# NUC400_v1 register map
File version: 1.0
Registers are 32-bit, read-write, reset 0x0 unless marked. A register's access mark holds for its fields unless they carry their own. Offsets are from the block's base; [hi:lo] are bit positions; {n}, {i} and the like mark numbered series; 'fields as' and 'values as' point back to an identical list.

## CLK — CLK Register Map
Base 0x40000200
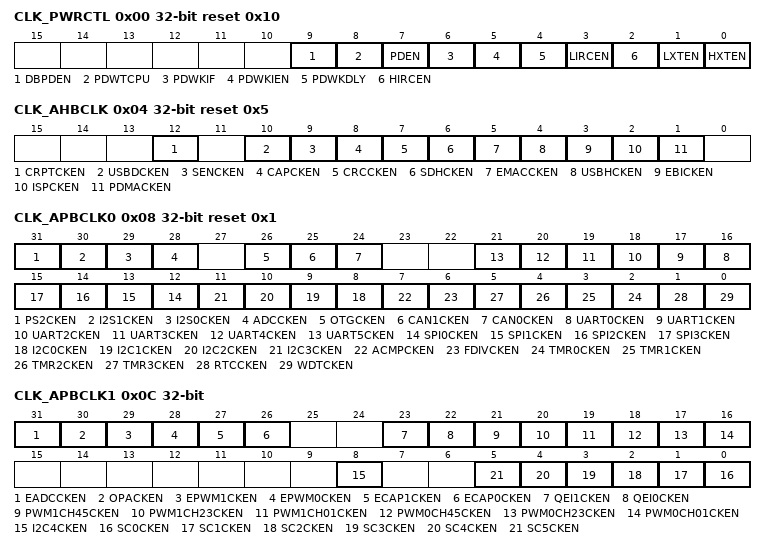
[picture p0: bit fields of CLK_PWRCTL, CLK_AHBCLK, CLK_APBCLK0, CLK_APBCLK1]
0x00 CLK_PWRCTL reset 0x10 (reset mask 0xFFFFFFF0) — System Power-down Control Register
  [9] DBPDEN — Chip Entering Power-Down Even ICE Connected
    0=Chip enters power-down disabled in Debug mode; 1=Chip enters power-down enabled in Debug mode
  [8] PDWTCPU — This Bit Control The Power-Down Entry Condition (Write Protect)
    0=Chip enters Power-down mode when the PDEN bit is set to 1; 1=Chip enters Power-down mode when the both PDWTCPU and PDEN bits are set to 1 and CPU run WFI instruction
  [7] PDEN — System Power-Down Enable Bit (Write Protect). When this bit is set to 1, Power-down mode is enabled and chip power-down behavior will depend on the PDWTCPU bit. (a) If the PDWTCPU is 0, then the chip enters Power-down mode immediately after the PDEN bit set. ( default) (b) if the PDWTCPU is 1, then the chip keeps active till the CPU sleep mode is also active and then the chip enters Power-down mode. When chip wakes up from Power-down mode, this bit is auto cleared. Users need to set this bit again for next power-down. In Power-down mode, HXT and the HIRC will be disabled in this mode, but the LXT and LIRC are not controlled by Power-down mode. In Power-down mode, the PLL and system clock are disabled, and ignored the clock source selection. The clocks of peripheral are not controlled by Power-down mode, if the peripheral clock source is from LXT or the LIRC.
    0=Chip operating normally or chip in idle mode by WFI command; 1=Chip enters Power-down mode instant or waits CPU sleep command WFI
  [6] PDWKIF — Power-Down Mode Wake-Up Interrupt Status. Set by "power-down wake-up event", it indicates that resume from Power-down mode" The flag is set if the GPIO, USB, UART, WDT, CAN, ACMP, BOD, RTC or SDHOST wake-up occurred. Note1: Write 1 to clear the bit to 0. Note2: This bit works only if PDWKIEN (CLK_PWRCTL[5]) set to 1.
  [5] PDWKIEN — Power-Down Mode Wake-Up Interrupt Enable Bit (Write Protect). Note: The interrupt will occur when both PDWKIF and PDWKIEN are high.
    0=Power-down Mode Wake-up Interrupt Disabled; 1=Power-down Mode Wake-up Interrupt Enabled
  [4] PDWKDLY — Wake-Up Delay Counter Enable Bit (Write Protect). When the chip wakes up from Power-down mode, the clock control will delay certain clock cycles to wait system clock stable. The delayed clock cycle is 4096 clock cycles when chip work at HXT, and 256 clock cycles when chip works at HIRC.
    0=Clock cycles delay Disabled; 1=Clock cycles delay Enabled
  [3] LIRCEN — 10 KHz Internal Low-Speed Oscillator (LIRC) Enable Bit (Write Protect)
    0=LIRC Disabled; 1=LIRC Enabled (default 1)
  [2] HIRCEN — 22.1184 MHz Internal High-Speed Oscillator Clock (HIRC) Enable Bit (Write Protect)
    0=HIRC Disabled; 1=HIRC Enabled
  [1] LXTEN — 32.768 KHz External Low-Speed Crystal Clock (LXT) Enable Bit (Write Protect)
    0=LXT Disabled; 1=LXT (Normal operation) Enabled
  [0] HXTEN — 4~24 MHz External High-Speed Crystal Clock (HXT) Enable Bit (Write Protect). The bit default value is set by flash controller user configuration register config0 [26:24]. When the default clock source is from 4~24 MHz external high-speed crystal, this bit is set to 1 automatically
    0=HXT Disabled; 1=HXT Enabled
0x04 CLK_AHBCLK reset 0x5 — AHB Devices Clock Enable Control Register
  [12] CRPTCKEN — Cryptographic Accelerator Clock Enable Bit
    0=Cryptographic Accelerator clock Disabled; 1=Cryptographic Accelerator clock Enabled
  [10] USBDCKEN — USB 2.0 Device Clock Enable Bit
    0=USB device controller's clock Disabled; 1=USB device controller's clock Enabled
  [9] SENCKEN — Sensor Clock Enable Bit
    0=Sensor clock Disabled; 1=Sensor clock Enabled
  [8] CAPCKEN — Image Capture Interface Controller Clock Enable Bit
    0=CAP controller's clock Disabled; 1=CAP controller's clock Enabled
  [7] CRCCKEN — CRC Generator Controller Clock Enable Bit
    0=CRC engine clock Disabled; 1=CRC engine clock Enabled
  [6] SDHCKEN — SDHOST Controller Clock Enable Bit
    0=SDHOST engine clock Disabled; 1=SDHOST engine clock Enabled
  [5] EMACCKEN — Ethernet Controller Clock Enable Bit (NUC472 Only)
    0=Ethernet Controller engine clock Disabled; 1=Ethernet Controller engine clock Enabled
  [4] USBHCKEN — USB HOST Controller Clock Enable Bit
    0=USB HOST engine clock Disabled; 1=USB HOST engine clock Enabled
  [3] EBICKEN — EBI Controller Clock Enable Bit
    0=EBI engine clock Disabled; 1=EBI engine clock Enabled
  [2] ISPCKEN — Flash ISP Controller Clock Enable Bit
    0=Flash ISP engine clock Disabled; 1=Flash ISP engine clock Enabled
  [1] PDMACKEN — PDMA Controller Clock Enable Bit
    0=PDMA engine clock Disabled; 1=PDMA engine clock Enabled
0x08 CLK_APBCLK0 reset 0x1 — APB Devices Clock Enable Control Register 0
  [31] PS2CKEN — PS/2 Clock Enable Bit
    0=PS/2 clock Disabled; 1=PS/2 clock Enabled
  [30] I2S1CKEN — I2S1 Clock Enable Bit
    0=I2S1 Clock Disabled; 1=I2S1 Clock Enabled
  [29] I2S0CKEN — I2S0 Clock Enable Bit
    0=I2S Clock Disabled; 1=I2S Clock Enabled
  [28] ADCCKEN — Analog-Digital-Converter (ADC) Clock Enable Bit
    0=ADC clock Disabled; 1=ADC clock Enabled
  [26] OTGCKEN — USB 2.0 OTG Device Controller Clock Enable Bit
    0=OTG clock Disabled; 1=OTG clock Enabled
  [25] CAN1CKEN — CAN Bus Controller-1 Clock Enable Bit
    0=CAN1 clock Disabled; 1=CAN1 clock Enabled
  [24] CAN0CKEN — CAN Bus Controller-0 Clock Enable Bit
    0=CAN0 clock Disabled; 1=CAN0 clock Enabled
  [n+16] UART{n}CKEN (n=0..5) — UART{n} Clock Enable Bit
    0=UART{n} clock Disabled; 1=UART{n} clock Enabled
  [n+12] SPI{n}CKEN (n=0..3) — SPI{n} Clock Enable Bit
    0=SPI{n} Clock Disabled; 1=SPI{n} Clock Enabled
  [n+8] I2C{n}CKEN (n=0..3) — I2C{n} Clock Enable Bit
    0=I2C{n} Clock Disabled; 1=I2C{n} Clock Enabled
  [7] ACMPCKEN — Analog Comparator Clock Enable Bit
    0=Analog Comparator Clock Disabled; 1=Analog Comparator Clock Enabled
  [6] FDIVCKEN — Frequency Divider Output Clock Enable Bit
    0=FDIV Clock Disabled; 1=FDIV Clock Enabled
  [n+2] TMR{n}CKEN (n=0..3) — Timer{n} Clock Enable Bit
    0=Timer{n} Clock Disabled; 1=Timer{n} Clock Enabled
  [1] RTCCKEN — Real-Time-Clock APB Interface Clock Enable Bit. This bit is used to control the RTC APB clock only, The RTC engine clock source is from the 32.768 kHz external low-speed crystal.
    0=RTC Clock Disabled; 1=RTC Clock Enabled
  [0] WDTCKEN — Watchdog Timer Clock Enable Bit (Write Protect). This bit is the protected bit, which means programming this needs to write "59h", "16h", "88h" to address 0x4000_0100 to disable register protection. Refer to the register REGWRPROT at address GCR_BA+0x100.
    0=Watchdog Timer Clock Disabled; 1=Watchdog Timer Clock Enabled
0x0C CLK_APBCLK1 — APB Devices Clock Enable Control Register 1
  [31] EADCCKEN — Enhanced Analog-Digital-Converter (E ADC) Clock Enable Bit
    0=EADC clock Disabled; 1=EADC clock Enabled
  [30] OPACKEN — OP Amplifier (OPA) Clock Enable Bit
    0=OPA clock Disabled; 1=OPA clock Enabled
  [29] EPWM1CKEN — Enhanced PWM1 (EPWM) Clock Enable Bit
    0=EPWM1 clock Disabled; 1=EPWM1 clock Enabled
  [28] EPWM0CKEN — Enhanced PWM0 (EPWM) Clock Enable Bit
    0=EPWM0 clock Disabled; 1=EPWM0 clock Enabled
  [27] ECAP1CKEN — Enhanced CAP (ECAP1) Clock Enable Bit
    0=ECAP1 clock Disabled; 1=ECAP1 clock Enabled
  [26] ECAP0CKEN — Enhanced CAP (ECAP0) Clock Enable Bit
    0=ECAP0 clock Disabled; 1=ECAP0 clock Enabled
  [23] QEI1CKEN — Quadrature Encoder Interface (QEI1) Clock Enable Bit
    0=QEI1 clock Disabled; 1=QEI1 clock Enabled
  [22] QEI0CKEN — Quadrature Encoder Interface (QEI0) Clock Enable Bit
    0=QEI0 clock Disabled; 1=QEI0 clock Enabled
  [21] PWM1CH45CKEN — PWM1_45 Clock Enable Bit
    0=PWM1_45 Clock Disabled; 1=PWM1_45 Clock Enabled
  [20] PWM1CH23CKEN — PWM1_23 Clock Enable Bit
    0=PWM1_23 Clock Disabled; 1=PWM1_23 Clock Enabled
  [19] PWM1CH01CKEN — PWM1_01 Clock Enable Bit
    0=PWM1_01 Clock Disabled; 1=PWM1_01 Clock Enabled
  [18] PWM0CH45CKEN — PWM0_45 Clock Enable Bit
    0=PWM0_45 Clock Disabled; 1=PWM0_45 Clock Enabled
  [17] PWM0CH23CKEN — PWM0_23 Clock Enable Bit
    0=PWM0_23 Clock Disabled; 1=PWM0_23 Clock Enabled
  [16] PWM0CH01CKEN — PWM0_01 Clock Enable Bit
    0=PWM0_01 Clock Disabled; 1=PWM0_01 Clock Enabled
  [8] I2C4CKEN — I2C4 Clock Enable Bit
    0=I2C4 Clock Disabled; 1=I2C4 Clock Enabled
  [n] SC{n}CKEN (n=0..5) — SC{n} Clock Enable Bit
    0=SC{n} Clock Disabled; 1=SC{n} Clock Enabled
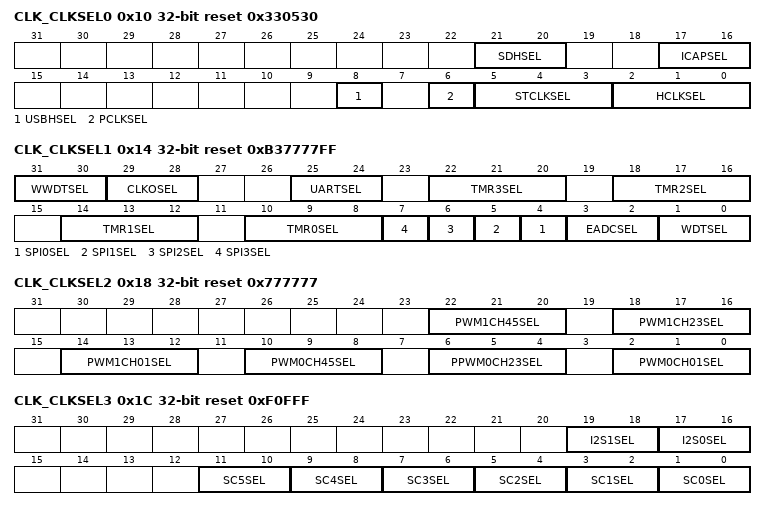
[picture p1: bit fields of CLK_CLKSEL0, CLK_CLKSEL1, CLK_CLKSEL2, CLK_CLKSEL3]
0x10 CLK_CLKSEL0 reset 0x330530 (reset mask 0xFFFFFFF0) — Clock Source Select Control Register 0
  [21:20] SDHSEL — SDHOST Engine Clock Source Selection. These bits are protected bit. It means programming this bit needs to write "59h", "16h", "88h" to address 0x4000_0100 to disable register protection. Refer to the register REGWRPROT at address GCR_BA+0x100.
    0=Clock source from HXT clock; 1=Clock source from PLL clock; 2=Clock source from HCLK; 3=Clock source from HIRC clock
  [17:16] ICAPSEL — Image Capture Interface Clock Source Selection. These bits are protected bit. It means programming this bit needs to write "59h", "16h", "88h" to address 0x4000_0100 to disable register protection. Refer to the register REGWRPROT at address GCR_BA+0x100.
    values as SDHSEL
  [8] USBHSEL — USB Host Clock Source Selection (Write Protect). These bits are protected bit. It means programming this bit needs to write "59h", "16h", "88h" to address 0x4000_0100 to disable register protection. Refer to the register REGWRPROT at address GCR_BA+0x100.
    0=Clock source from PLL2; 1=Clock source from PLL
  [6] PCLKSEL — PCLK Clock Source Selection (Write Protect). These bits are protected bit. It means programming this bit needs to write "59h", "16h", "88h" to address 0x4000_0100 to disable register protection. Refer to the register REGWRPROT at address GCR_BA+0x100.
    0=Clock source from HCLK; 1=Clock source from HCLK/2
  [5:3] STCLKSEL — Cortex-M4 SysTick Clock Source Selection (Write Protect)
    0=Clock source from HXT clock; 1=Clock source from LXT clock; 2=Clock source from HXT clock/2; 3=Clock source from HCLK/2; 7=Clock source from HIRC clock/2
  [2:0] HCLKSEL — HCLK Clock Source Selection (Write Protect). Before clock switching, the related clock sources (both pre-select and new-select) must be turned on. The 3-bit default value is reloaded from the value of CFOSC (Config0[26:24]) in user configuration register of Flash controller by any reset. Therefore the default value is either 000b or 111b. These bits are protected bit, it means programming this bit needs to write "59h", "16h", "88h" to address 0x4000_0100 to disable register protection. Refer to the register REGWRPROT at address GCR_BA+0x100.
    0=Clock source from HXT clock; 1=Clock source from LXT clock; 2=Clock source from PLL clock; 3=Clock source from LIRC clock; 4=Clock source from PLL2 clock; 7=Clock source from HIRC clock
0x14 CLK_CLKSEL1 reset 0xB37777FF — Clock Source Select Control Register 1
  [31:30] WWDTSEL — Window Watchdog Timer Clock Source Selection
    2=Clock source from HCLK/2048 clock; 3=Clock source from LIRC clock
  [29:28] CLKOSEL — Clock Divider Clock Source Selection
    0=Clock source from HXT clock; 1=Clock source from LXT clock; 2=Clock source from HCLK; 3=Clock source from HIRC clock
  [25:24] UARTSEL — UART Clock Source Selection
    0=Clock source from HXT clock; 1=Clock source from PLL clock
  [4n+10:4n+8] TMR{n}SEL (n=0..3) — TIMER{n} Clock Source Selection
    0=Clock source from HXT clock; 1=Clock source from LXT clock; 2=Clock source from PCLK; 3=Clock source from external trigger; 5=Clock source from LIRC clock; 7=Clock source from HIRC clock
  [n+4] SPI{n}SEL (n=0..3) — SPI{n} Clock Source Selection
    0=Clock source from PLL clock; 1=Clock source from PCLK
  [3:2] EADCSEL — ADC Clock Source Selection
    0=Clock source from HXT clock; 1=Clock source from PLL clock; 2=Clock source from PCLK; 3=Clock source from HIRC clock
  [1:0] WDTSEL — Watchdog Timer Clock Source Selection (Write Protect). These bits are protected bit,and programming this needs to write "59h", "16h", "88h" to address 0x4000_0100 to disable register protection. Refer to the register REGWRPROT at address GCR_BA+0x100.
    0=Clock source from 4~24 MHz external high-speed crystal clock; 1=Clock source from LXT clock; 2=Clock source from HCLK/2048 clock; 3=Clock source from LIRC clock
0x18 CLK_CLKSEL2 reset 0x777777 — Clock Source Select Control Register 2
  [all] fields
    0=Clock source from HXT clock; 1=Clock source from LXT clock; 2=Clock source from PCLK; 3=Clock source from HIRC clock; 4=Clock source from LIRC clock
  [22:20] PWM1CH45SEL — PWM1_4 And PWM1_5 Clock Source Selection. PWM1_4 and PWM1_5 used the same Engine clock source; both of them use the same prescaler. The Engine clock source of PWM1_4 and PWM1_5 is defined by PWM1CH45SEL[2:0]
  [18:16] PWM1CH23SEL — PWM1_2 And PWM1_3 Clock Source Selection. PWM1_2 and PWM1_3 uses the same Engine clock source, both of them use the same prescaler. The Engine clock source of PWM1_2 and PWM1_3 is defined by PWM1CH23SEL[2:0]
  [14:12] PWM1CH01SEL — PWM1_0 And PWM1_1 Clock Source Selection. PWM1_0 and PWM1_1 uses the same Engine clock source, both of them use the same prescaler. The Engine clock source of PWM1_0 and PWM1_1 is defined by PWM1CH01SEL[2:0]
  [10:8] PWM0CH45SEL — PWM0_4 And PWM0_5 Clock Source Selection. PWM0_4 and PWM0_5 used the same Engine clock source; both of them use the same prescaler. The Engine clock source of PWM0_4 and PWM0_5 is defined by PWM0CH45SEL[2:0]
  [6:4] PPWM0CH23SEL — PWM0_2 And PWM0_3 Clock Source Selection. PWM0_2 and PWM0_3 uses the same Engine clock source, both of them use the same prescaler. The Engine clock source of PWM0_2 and PWM0_3 is defined by PPWM0CH23SEL[2:0]
  [2:0] PWM0CH01SEL — PWM0_0 And PWM0_1 Clock Source Selection. PWM0_0 and PWM0_1 uses the same Engine clock source, both of them use the same prescaler. The Engine clock source of PWM0_0 and PWM0_1 is defined by PWM0CH01SEL[2:0]
0x1C CLK_CLKSEL3 reset 0xF0FFF — Clock Source Select Control Register 3
  [19:18] I2S1SEL — I2S1 Clock Source Selection
    values as CLK_CLKSEL1.EADCSEL
  [17:16] I2S0SEL — I2S0 Clock Source Selection
    values as CLK_CLKSEL1.EADCSEL
  [2n+1:2n] SC{n}SEL (n=0..5) — SC{n} Clock Source Selection
    0=Clock source from HXT clock; 1=Clock source from PLL clock; 2=PCLK; 3=Clock source from HIRC clock
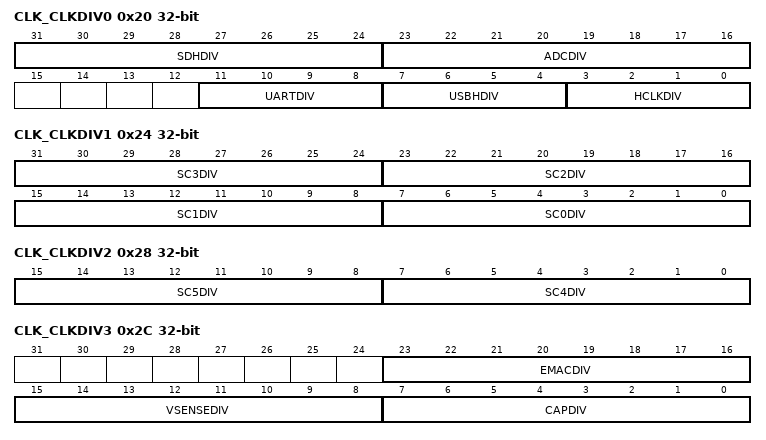
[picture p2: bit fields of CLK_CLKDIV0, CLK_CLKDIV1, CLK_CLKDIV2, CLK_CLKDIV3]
0x20 CLK_CLKDIV0 — Clock Divider Number Register 0
  [31:24] SDHDIV — SDHOST Clock Divide Number From SDHOST Clock Source
  [23:16] ADCDIV — ADC Clock Divide Number From ADC Clock Source
  [11:8] UARTDIV — UART Clock Divide Number From UART Clock Source
  [7:4] USBHDIV — USB Host Clock Divide Number From PLL Clock
  [3:0] HCLKDIV — HCLK Clock Divide Number From HCLK Clock Source
0x24 CLK_CLKDIV1 — Clock Divider Number Register 1
  [8n+7:8n] SC{n}DIV (n=0..3) — SC{n} Clock Divide Number From SC{n} Clock Source
0x28 CLK_CLKDIV2 — Clock Divider Number Register 2
  [15:8] SC5DIV — SC5 Clock Divide Number From SC5 Clock Source
  [7:0] SC4DIV — SC4 Clock Divide Number From SC4 Clock Source
0x2C CLK_CLKDIV3 — Clock Divider Number Register 3
  [23:16] EMACDIV — Ethernet Clock Divide Number Form HCLK (NUC472 Only)
  [15:8] VSENSEDIV — Video Pixel Clock Divide Number From ICAP Clock Source
  [7:0] CAPDIV — Image Capture Seneor Clock Divide Number From ICAP Clock Source
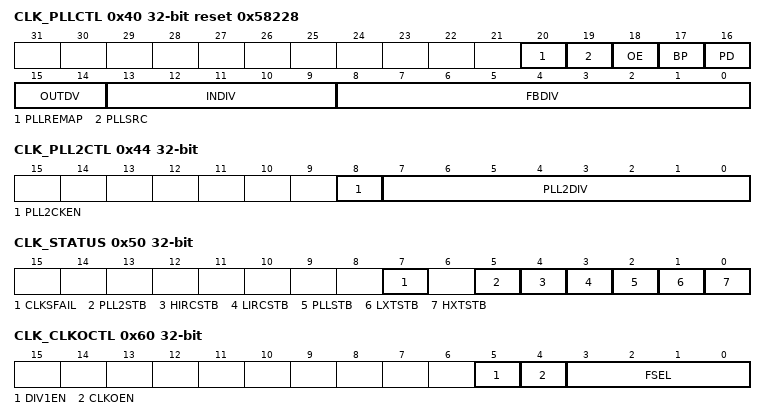
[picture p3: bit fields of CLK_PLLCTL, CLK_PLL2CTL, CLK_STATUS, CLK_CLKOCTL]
0x40 CLK_PLLCTL reset 0x58228 — PLL Control Register
  [20] PLLREMAP — PLL Remap Enable Bit
    0=PLL remap enable; 1=PLL remap disable
  [19] PLLSRC — PLL Source Clock Selection
    0=PLL source clock from HXT; 1=PLL source clock from HIRC
  [18] OE — PLL OE (FOUT Enable) Pin Control
    0=PLL FOUT Enabled; 1=PLL FOUT is fixed low
  [17] BP — PLL Bypass Control
    0=PLL is in normal mode (default); 1=PLL clock output is same as clock input (XTALin)
  [16] PD — Power-Down Mode. If set the PDEN bit to 1 in CLK_PWRCTL register, the PLL will enter Power-down mode, too.
    0=PLL is in normal mode; 1=PLL is in Power-down mode (default)
  [15:14] OUTDV — PLL Output Divider Control Pins. Refer to the formulas below the table.
  [13:9] INDIV — PLL Input Divider Control Pins. Refer to the formulas below the table.
  [8:0] FBDIV — PLL Feedback Divider Control Pins. Refer to the formulas below the table.
0x44 CLK_PLL2CTL — PLL2 Control Register
  [8] PLL2CKEN — USB PHY 480 MHz Enable Bit. This bit enables USB PHY PLL (480 MHz), and user needs to care the extenal crystal is 12 MHz or 24 MHz source. Note: Refer to OTG_PHYCTL[8] register to set the exteranl crystal frequency HXT.
    0=USB PHY PLL (480 MHz) Disabled; 1=USB PHY PLL (480 MHz) Enabled
  [7:0] PLL2DIV — PLL2 Divider Control. Note: Max. PLL2 frequency is 240 MHz when HXT is1 2 MHz.
0x50 CLK_STATUS (reset mask 0xFFFFFF00) — Clock Status Monitor Register
  [7] CLKSFAIL — Clock Switching Fail Flag. Note1: This bit is updated when software switches system clock source. If switch target clock is stable, this bit will be set to 0. If switch target clock is not stable, this bit will be set to 1. Note2: Write 1 to clear the bit to 0.
    0=Clock switching success; 1=Clock switching failure
  [5] PLL2STB — Internal PLL2 Clock Source Stable Flag. Note: This bit is read only.
    0=Internal PLL2 clock is not stable or disabled; 1=Internal PLL2 clock is stable
  [4] HIRCSTB — 22.1184 MHz Internal High-Speed Oscillator Clock (HIRC) Clock Source Stable Flag. Note: This bit is read only.
    0=HIRC clock is not stable or disabled; 1=HIRC clock is stable
  [3] LIRCSTB — 10 KHz Internal Low-Speed Oscillator Clock (LIRC)Source Stable Flag. Note: This bit is read only.
    0=LIRC clock is not stable or disabled; 1=LIRC clock is stable
  [2] PLLSTB — Internal PLL Clock Source Stable Flag. Note: This bit is read only.
    0=Internal PLL clock is not stable or disabled; 1=Internal PLL clock is stable
  [1] LXTSTB — 32.768 KHz External Low-Speed Crystal Clock(LXT) Source Stable Flag. Note: This is read only.
    0=LXT clock is not stable or disabled; 1=LXT clock is stabled
  [0] HXTSTB — 4~24 MHz External High-Speed Crystal Clock(HXT) Source Stable Flag. Note: This bit is read only.
    0=HXT clock is not stable or disabled; 1=HXT clock is stable
0x60 CLK_CLKOCTL — Frequency Divider Control Register
  [5] DIV1EN — Frequency Divider 1 Enable Bit
    0=Divider output frequency is dependent on FSEL value when FDIVEN is enabled; 1=Divider output frequency is input clock frequency
  [4] CLKOEN — Clock Output Enable Bit
    0=Clock output disabled; 1=Clock output enabled
  [3:0] FSEL — Divider Output Frequency Selection. The formula of output frequency is: Fin is the input clock frequency. Fout is the frequency of divider output clock. N is the 4-bit value of FSEL[3:0].
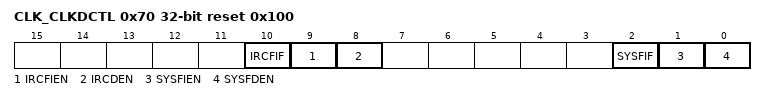
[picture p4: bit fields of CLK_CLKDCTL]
0x70 CLK_CLKDCTL reset 0x100 — Clock Fail Detector Control Register
  [10] IRCFIF — Internal RC Clock Fail Flag
    0=IRC clock normal; 1=IRC abnormal (write "1" to clear)
  [9] IRCFIEN — Internal RC Clock Detector Interrupt Enable Bit
    0=IRC clock fail interrupt disabled; 1=IRC clock fail interrupt enabled
  [8] IRCDEN — Internal RC Clock Detector Enable Bit
    values as IRCFIEN
  [2] SYSFIF — System Clock Detect Fail Flag
    0=System clock normal; 1=System clock abnormal (write " 1" to clear)
  [1] SYSFIEN — System Clock Detector Interrupt Enable Bit
    0=system clock fail interrupt disabled; 1=system clock fail interrupt enabled
  [0] SYSFDEN — System Clock Detector Enable Bit
    values as SYSFIEN
